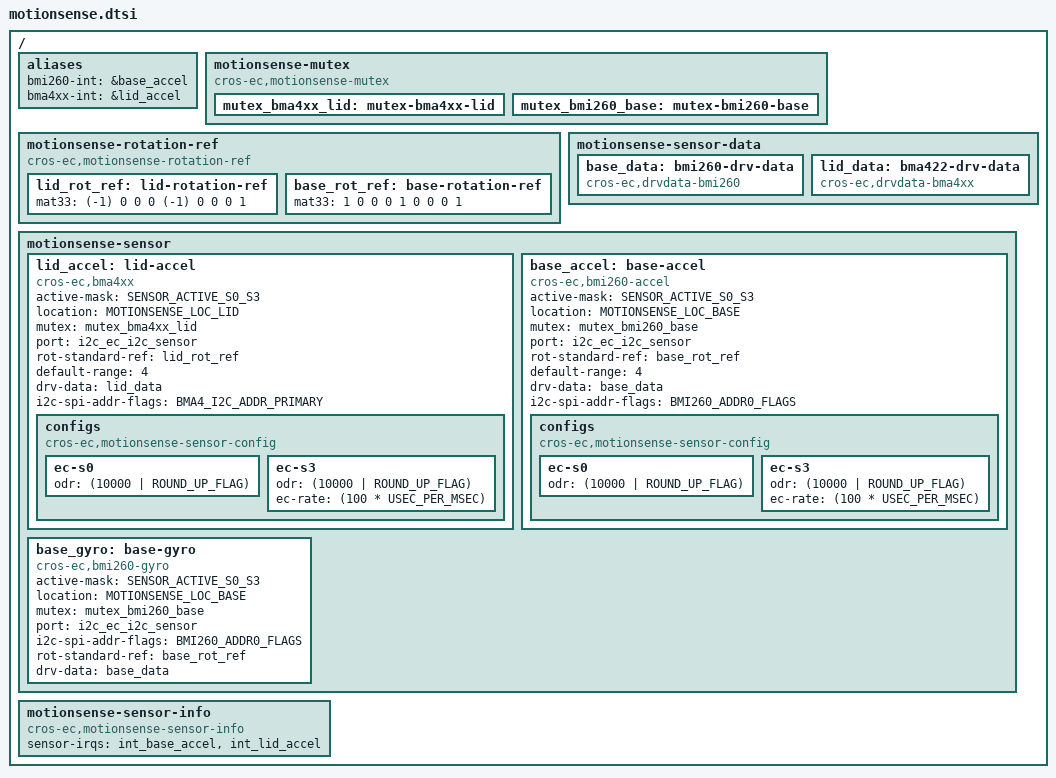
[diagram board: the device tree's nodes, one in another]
/* Copyright 2026 The ChromiumOS Authors
 * Use of this source code is governed by a BSD-style license that can be
 * found in the LICENSE file.
 */

#include <dt-bindings/motionsense/utils.h>

/ {
	aliases {
		/*
		 * motion sense's <>_INT_EVENT is handled by alias. Using the
		 * alias, each driver creates its own <>_INT_EVENT.
		 */
		bmi260-int = &base_accel;
		bma4xx-int = &lid_accel;
	};

	motionsense-mutex {
		compatible = "cros-ec,motionsense-mutex";
		mutex_bma4xx_lid: mutex-bma4xx-lid {
		};
		mutex_bmi260_base: mutex-bmi260-base {
		};
	};

	/* Rotation matrix used by drivers. */
	motionsense-rotation-ref {
		compatible = "cros-ec,motionsense-rotation-ref";
		lid_rot_ref: lid-rotation-ref {
			mat33 = <(-1) 0 0
				 0 (-1) 0
				 0 0 1>;
		};
		base_rot_ref: base-rotation-ref {
			mat33 = <1 0 0
				 0 1 0
				 0 0 1>;
		};
	};

	/* Driver specific data */
	motionsense-sensor-data {
		base_data: bmi260-drv-data {
			compatible = "cros-ec,drvdata-bmi260";
			status = "okay";
		};
		lid_data: bma422-drv-data {
			compatible = "cros-ec,drvdata-bma4xx";
			status = "okay";
		};
	};

	/* List of motion sensors that create motion_sensors array. */
	motionsense-sensor {
		lid_accel: lid-accel {
			compatible = "cros-ec,bma4xx";
			status = "okay";

			active-mask = "SENSOR_ACTIVE_S0_S3";
			location = "MOTIONSENSE_LOC_LID";
			mutex = <&mutex_bma4xx_lid>;
			port = <&i2c_ec_i2c_sensor>;
			rot-standard-ref = <&lid_rot_ref>;
			default-range = <4>;
			drv-data = <&lid_data>;
			i2c-spi-addr-flags = "BMA4_I2C_ADDR_PRIMARY";
			configs {
				compatible =
					"cros-ec,motionsense-sensor-config";
				ec-s0 {
					odr = <(10000 | ROUND_UP_FLAG)>;
				};
				ec-s3 {
					odr = <(10000 | ROUND_UP_FLAG)>;
					ec-rate = <(100 * USEC_PER_MSEC)>;
				};
			};
		};

		base_accel: base-accel {
			compatible = "cros-ec,bmi260-accel";
			status = "okay";

			active-mask = "SENSOR_ACTIVE_S0_S3";
			location = "MOTIONSENSE_LOC_BASE";
			mutex = <&mutex_bmi260_base>;
			port = <&i2c_ec_i2c_sensor>;
			rot-standard-ref = <&base_rot_ref>;
			default-range = <4>;
			drv-data = <&base_data>;
			i2c-spi-addr-flags = "BMI260_ADDR0_FLAGS";
			configs {
				compatible =
					"cros-ec,motionsense-sensor-config";
				ec-s0 {
					odr = <(10000 | ROUND_UP_FLAG)>;
				};
				ec-s3 {
					odr = <(10000 | ROUND_UP_FLAG)>;
					ec-rate = <(100 * USEC_PER_MSEC)>;
				};
			};
		};

		base_gyro: base-gyro {
			compatible = "cros-ec,bmi260-gyro";
			status = "okay";

			active-mask = "SENSOR_ACTIVE_S0_S3";
			location = "MOTIONSENSE_LOC_BASE";
			mutex = <&mutex_bmi260_base>;
			port = <&i2c_ec_i2c_sensor>;
			i2c-spi-addr-flags = "BMI260_ADDR0_FLAGS";
			rot-standard-ref = <&base_rot_ref>;
			drv-data = <&base_data>;
		};
	};

	/* High level description info */
	motionsense-sensor-info {
		compatible = "cros-ec,motionsense-sensor-info";

		/*
		 * List of GPIO interrupts that have to be enabled at initial
		 * stage.
		 */
		sensor-irqs = <&int_base_accel &int_lid_accel>;

		/* List of sensors in force mode */
	};
};
